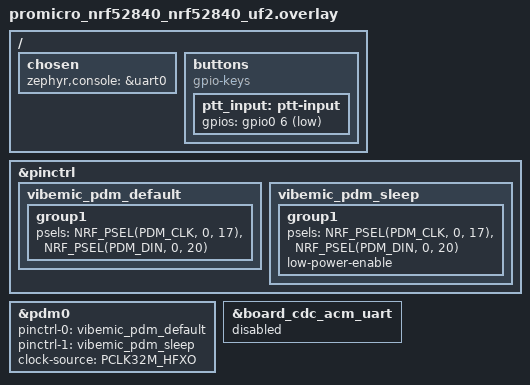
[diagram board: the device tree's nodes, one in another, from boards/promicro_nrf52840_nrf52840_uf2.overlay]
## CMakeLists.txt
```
cmake_minimum_required(VERSION 3.20.0)
find_package(Zephyr REQUIRED HINTS $ENV{ZEPHYR_BASE})
project(vibemic_transmitter)
target_include_directories(app PRIVATE ../common)
target_sources(app PRIVATE src/capture.c)

if(CONFIG_VIBEMIC_MIC_PROBE)
  target_sources(app PRIVATE src/mic_probe.c)
else()
  target_sources(app PRIVATE src/main.c src/dynamics.c src/battery.c ../common/link.c ../common/protocol.c)
endif()

target_sources_ifdef(CONFIG_VIBEMIC_DIRECT_USB app PRIVATE
                     ../common/usb.c ../common/session.c ../common/playout.c)
```

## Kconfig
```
mainmenu "VibeMic transmitter"

source "Kconfig.zephyr"

config VIBEMIC_MIC_PROBE
	bool "Capture a three-second PCM clip over USB CDC ACM"

config VIBEMIC_APPROVAL_GESTURE
	bool "Distinguish a double tap from a dictation hold"
	default y if BOARD_PROMICRO_NRF52840

config VIBEMIC_DIRECT_USB
	bool "Offer the microphone and PTT directly to a USB host"
	default y if BOARD_PROMICRO_NRF52840
	depends on BOARD_PROMICRO_NRF52840 && !VIBEMIC_MIC_PROBE
	select USB_DEVICE_STACK_NEXT
	select USBD_AUDIO2_CLASS
	select USBD_HID_SUPPORT
	select HWINFO

choice VIBEMIC_BATTERY_SENSOR
	prompt "Transmitter battery measurement circuit"
	default VIBEMIC_BATTERY_NONE
	depends on BOARD_PROMICRO_NRF52840 && !VIBEMIC_MIC_PROBE

config VIBEMIC_BATTERY_NONE
	bool "Unknown circuit (report power only)"

config VIBEMIC_BATTERY_VDDH
	bool "nice!nano v2: internal VDDH / 5"
	select ADC

config VIBEMIC_BATTERY_DIVIDER
	bool "nice!nano v1: AIN2, 806k + 2M divider"
	select ADC

endchoice
```

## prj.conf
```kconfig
CONFIG_AUDIO=y
CONFIG_AUDIO_DMIC=y
CONFIG_REGULATOR=y
CONFIG_GPIO=y
CONFIG_CLOCK_CONTROL=y
CONFIG_ENTROPY_GENERATOR=y
CONFIG_ENTROPY_DEVICE_RANDOM_GENERATOR=y

CONFIG_ESB=y
CONFIG_ESB_CLOCK_INIT=y
CONFIG_ESB_MAX_PAYLOAD_LENGTH=172
CONFIG_ESB_PIPE_COUNT=1
CONFIG_ESB_DEFAULT_RF_CHANNEL=76

CONFIG_MAIN_STACK_SIZE=2048
CONFIG_BOARD_SERIAL_BACKEND_CDC_ACM=n
CONFIG_LOG=y
CONFIG_SERIAL=y
CONFIG_CONSOLE=y
CONFIG_UART_CONSOLE=y
```

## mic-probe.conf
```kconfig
CONFIG_VIBEMIC_MIC_PROBE=y
CONFIG_AUDIO=y
CONFIG_AUDIO_DMIC=y
CONFIG_REGULATOR=y
CONFIG_CLOCK_CONTROL=y
CONFIG_USB_DEVICE_STACK_NEXT=y
CONFIG_CDC_ACM_SERIAL_INITIALIZE_AT_BOOT=y
CONFIG_CDC_ACM_SERIAL_VID=0x1209
CONFIG_CDC_ACM_SERIAL_PID=0x0002
CONFIG_CDC_ACM_SERIAL_MANUFACTURER_STRING="VibeMic"
CONFIG_CDC_ACM_SERIAL_PRODUCT_STRING="VibeMic PDM Probe"
CONFIG_UART_CONSOLE=n
CONFIG_UART_LINE_CTRL=y
CONFIG_MAIN_STACK_SIZE=2048
```

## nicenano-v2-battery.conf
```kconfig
# Only use on a confirmed nice!nano v2 power circuit, not an unverified clone.
CONFIG_VIBEMIC_BATTERY_VDDH=y
```

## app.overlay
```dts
#include <zephyr/dt-bindings/gpio/gpio.h>

/ {
	chosen {
		zephyr,console = &uart0;
	};

	buttons {
		compatible = "gpio-keys";

		ptt_input: ptt-input {
			gpios = <&xiao_d 0 (GPIO_PULL_UP | GPIO_ACTIVE_LOW)>;
		};
	};

	msm261d3526hicpm-c-en {
		regulator-boot-on;
	};
};

&pdm0 {
	status = "okay";
	clock-source = "PCLK32M_HFXO";
};

&board_cdc_acm_uart {
	status = "disabled";
};
```

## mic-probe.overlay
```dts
&board_cdc_acm_uart {
	status = "okay";
	hw-flow-control; /* uart_poll_out waits for TX space instead of discarding bytes. */
};
```

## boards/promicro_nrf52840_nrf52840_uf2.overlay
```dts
#include <zephyr/dt-bindings/gpio/gpio.h>
#include <zephyr/dt-bindings/pinctrl/nrf-pinctrl.h>
#include "../../common/usb-audio.dtsi"

/ {
	chosen {
		zephyr,console = &uart0;
	};

	buttons {
		compatible = "gpio-keys";

		ptt_input: ptt-input {
			gpios = <&gpio0 6 (GPIO_PULL_UP | GPIO_ACTIVE_LOW)>;
		};
	};
};

&pinctrl {
	vibemic_pdm_default: vibemic_pdm_default {
		group1 {
			psels = <NRF_PSEL(PDM_CLK, 0, 17)>,
				<NRF_PSEL(PDM_DIN, 0, 20)>;
		};
	};

	vibemic_pdm_sleep: vibemic_pdm_sleep {
		group1 {
			psels = <NRF_PSEL(PDM_CLK, 0, 17)>,
				<NRF_PSEL(PDM_DIN, 0, 20)>;
			low-power-enable;
		};
	};
};

&pdm0 {
	status = "okay";
	pinctrl-0 = <&vibemic_pdm_default>;
	pinctrl-1 = <&vibemic_pdm_sleep>;
	pinctrl-names = "default", "sleep";
	clock-source = "PCLK32M_HFXO";
};

&board_cdc_acm_uart {
	status = "disabled";
};
```

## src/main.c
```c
#include "capture.h"
#include "battery.h"
#include "dynamics.h"
#include "link.h"
#include "protocol.h"
#include "ptt_gesture.h"
#include "session.h"
#include "usb.h"

#include <errno.h>
#include <string.h>
#include <zephyr/drivers/gpio.h>
#include <zephyr/kernel.h>
#include <zephyr/logging/log.h>
#include <zephyr/random/random.h>
#include <zephyr/sys/atomic.h>

LOG_MODULE_REGISTER(vibemic_tx, LOG_LEVEL_INF);

#define HOLD_BLOCKS (IS_ENABLED(CONFIG_VIBEMIC_APPROVAL_GESTURE) ? VM_HOLD_BLOCKS : 0u)
#define PRE_ROLL_BLOCKS (120u / VM_BLOCK_MS + HOLD_BLOCKS)
#define TX_QUEUE_BLOCKS (40u + HOLD_BLOCKS)
#define DEBOUNCE_BLOCKS 2u
#define UP_RESTARTS 2u
#define UP_RESTART_DELAY_MS 12u

static const struct gpio_dt_spec ptt = GPIO_DT_SPEC_GET(DT_NODELABEL(ptt_input), gpios);
static const struct gpio_dt_spec led = GPIO_DT_SPEC_GET(DT_ALIAS(led0), gpios);
static int16_t pre_roll[PRE_ROLL_BLOCKS][VM_BLOCK_SAMPLES];

K_MSGQ_DEFINE(tx_queue, sizeof(struct esb_payload), TX_QUEUE_BLOCKS, 4);
K_SEM_DEFINE(tx_done, 0, 1);
static atomic_t tx_attempts;
static atomic_t tx_ok;

static void on_radio(const struct esb_evt *event)
{
	if (event->evt_id == ESB_EVENT_TX_SUCCESS || event->evt_id == ESB_EVENT_TX_FAILED) {
		atomic_set(&tx_attempts, event->tx_attempts);
		atomic_set(&tx_ok, event->evt_id == ESB_EVENT_TX_SUCCESS);
		k_sem_give(&tx_done);
	}
}

static bool send_packet(const struct esb_payload *packet, uint32_t *retries)
{
	int err = esb_write_payload(packet);
	unsigned restarts = packet->data[1] == VM_PTT_UP ? UP_RESTARTS : 0u;

	if (err != 0) {
		LOG_WRN("ESB write: %d", err);
		return false;
	}
	for (;;) {
		k_sem_take(&tx_done, K_FOREVER);
		uint32_t attempts = atomic_get(&tx_attempts);

		*retries += attempts > 0 ? attempts - 1u : 0u;
		if (atomic_get(&tx_ok)) {
			return true;
		}
		if (restarts == 0) {
			break;
		}
		restarts--;
		/* On TX_FAILED ESB retains the payload and PID. Spread the final
		 * edge across separate bursts without enqueuing another packet.
		 */
		k_sleep(K_MSEC(UP_RESTART_DELAY_MS));
		err = esb_start_tx();
		if (err != 0) {
			LOG_WRN("ESB restart: %d", err);
			break;
		}
		(*retries)++;
	}
	err = esb_flush_tx();
	if (err != 0) {
		LOG_WRN("ESB flush: %d", err);
	}
	return false;
}

static void radio_worker(void *a, void *b, void *c)
{
	struct esb_payload packet;
	uint32_t sent = 0, failed = 0, retries = 0;
	uint64_t ack_sum_us = 0;
	uint32_t ack_max_us = 0;

	ARG_UNUSED(a);
	ARG_UNUSED(b);
	ARG_UNUSED(c);
	for (;;) {
		k_msgq_get(&tx_queue, &packet, K_FOREVER);

		/* Only one item in the ESB FIFO. */
		uint32_t started = k_cycle_get_32();
		if (send_packet(&packet, &retries)) {
			uint32_t elapsed = k_cyc_to_us_ceil32(k_cycle_get_32() - started);

			sent++;
			ack_sum_us += elapsed;
			ack_max_us = MAX(ack_max_us, elapsed);
		} else {
			failed++;
		}
		if (packet.data[1] == VM_PTT_UP) {
			uint32_t ack_avg_us = sent ? ack_sum_us / sent : 0;

			LOG_INF("Session TX: %u ACK, %u failed, %u retries, ACK avg/max %u/%u us",
				sent, failed, retries, ack_avg_us, ack_max_us);
			sent = failed = retries = 0;
			ack_sum_us = ack_max_us = 0;
		}
	}
}

K_THREAD_STACK_DEFINE(radio_stack, 1536);
static struct k_thread radio_thread;

static bool enqueue(uint8_t flag, uint32_t session, uint32_t block, const int16_t *pcm)
{
	struct esb_payload packet = {
		.pipe = 0,
		.noack = false,
		.length = flag == VM_AUDIO ? VM_AUDIO_BYTES : VM_HEADER_BYTES,
	};

	/* Preserve room for both edges even when audio is backed up. */
	if (flag == VM_AUDIO && k_msgq_num_free_get(&tx_queue) <= 2u) {
		return false;
	}
	vm_encode(packet.data, flag, session, block, pcm);
	if (k_msgq_put(&tx_queue, &packet, K_NO_WAIT) != 0) {
		LOG_WRN("TX queue full; dropped PTT edge %u", flag);
		return false;
	}
	return true;
}

static bool send_audio(uint32_t usb, enum vm_flag flag, uint32_t session,
		       uint32_t block, const int16_t *pcm)
{
	if (IS_ENABLED(CONFIG_VIBEMIC_DIRECT_USB) && usb) {
		uint8_t wire[VM_AUDIO_BYTES];

		if (usb != vm_usb_connection()) {
			return false;
		}
		vm_encode(wire, flag, session, block, pcm);
		vm_session_accept(wire, flag == VM_AUDIO ? VM_AUDIO_BYTES : VM_HEADER_BYTES,
				  0, k_uptime_get_32());
		return true;
	}
	return enqueue(flag, session, block, pcm);
}

int main(void)
{
	int16_t pcm[VM_BLOCK_SAMPLES];
	uint32_t session = sys_rand32_get();
	uint32_t block = 0;
	uint32_t dropped = 0;
	uint32_t capture_block = 0;
	uint32_t usb = 0, press_usb = 0;
	uint32_t battery_at = 0;
	unsigned write = 0, have = 0, debounce = 0;
	struct vm_ptt_gesture ptt_state = {0};
	struct vm_dynamics dynamics;
	int err;

	if (!gpio_is_ready_dt(&ptt) || !gpio_is_ready_dt(&led)) {
		return -ENODEV;
	}
	err = gpio_pin_configure_dt(&ptt, GPIO_INPUT);
	if (err == 0) {
		err = gpio_pin_configure_dt(&led, GPIO_OUTPUT_INACTIVE);
	}
	if (err == 0) {
		err = vm_radio_init(ESB_MODE_PTX, on_radio);
	}
	if (err == 0) {
		err = vm_capture_start();
	}
	if (err != 0) {
		LOG_ERR("TX initialization failed: %d", err);
		return err;
	}
	if (IS_ENABLED(CONFIG_VIBEMIC_DIRECT_USB)) {
		err = vm_usb_init();
		if (err != 0) {
			LOG_WRN("Direct USB initialization failed: %d", err);
		}
	}

	k_thread_create(&radio_thread, radio_stack, K_THREAD_STACK_SIZEOF(radio_stack),
			radio_worker, NULL, NULL, NULL, 4, 0, K_NO_WAIT);
	vm_dynamics_reset(&dynamics);
	vm_battery_start();

	for (;;) {
		err = vm_capture_read(pcm);
		if (err != 0) {
			/* Release on capture failure; RX watchdog covers a lost UP. */
			if (ptt_state.recording && !press_usb) {
				enqueue(VM_PTT_UP, session, block, NULL);
			}
			if (IS_ENABLED(CONFIG_VIBEMIC_DIRECT_USB)) {
				vm_usb_stop();
			}
			gpio_pin_set_dt(&led, 0);
			vm_capture_stop();
			LOG_ERR("PDM stopped: %d; reset transmitter to retry", err);
			return err;
		}
		vm_dynamics_process(&dynamics, pcm);

		if (IS_ENABLED(CONFIG_VIBEMIC_DIRECT_USB) && usb != vm_usb_connection()) {
			usb = vm_usb_connection();
			vm_session_reset();
			ptt_state.armed = false;
			if (press_usb && ptt_state.recording) {
				gpio_pin_set_dt(&led, 0);
			}
		}
		int level = gpio_pin_get_dt(&ptt);
		bool pressed = ptt_state.pressed;

		if (level < 0 || (level != 0) == pressed) {
			debounce = 0;
		} else if (++debounce == DEBOUNCE_BLOCKS) {
			debounce = 0;
			pressed = level != 0;
		}
		if (pressed && !ptt_state.pressed) {
			/* Keep the same output for the whole press, including its audio tail. */
			press_usb = usb;
		}
		enum vm_flag event = vm_ptt_step(&ptt_state, pressed, capture_block++,
					       IS_ENABLED(CONFIG_VIBEMIC_APPROVAL_GESTURE));

		if (event == VM_PTT_DOWN) {
			session++;
			block = 0;
			dropped = 0;
			send_audio(press_usb, VM_PTT_DOWN, session, block, NULL);
			gpio_pin_set_dt(&led, !press_usb || press_usb == usb);
			for (unsigned i = 0; i < have; i++) {
				unsigned index = (write + PRE_ROLL_BLOCKS - have + i) %
						 PRE_ROLL_BLOCKS;
				if (!send_audio(press_usb, VM_AUDIO, session, block++, pre_roll[index])) {
					dropped++;
				}
			}
		}
		if (ptt_state.recording || event == VM_PTT_UP) {
			if (!send_audio(press_usb, VM_AUDIO, session, block++, pcm)) {
				dropped++;
			}
		}
		if (event == VM_PTT_UP) {
			/* The UP fence carries the exact end timestamp, even if audio was lost. */
			send_audio(press_usb, VM_PTT_UP, session, block, NULL);
			gpio_pin_set_dt(&led, 0);
			if (dropped != 0) {
				LOG_WRN("TX queue dropped %u audio blocks", dropped);
			}
		}
		if (event == VM_APPROVAL_ARM) {
			session++;
		}
		if (event == VM_APPROVAL_ARM || event == VM_APPROVAL_COMMIT) {
			/* Keep the gesture on one transport and out of the radio audio backlog. */
			if (press_usb == usb && (usb || k_msgq_num_used_get(&tx_queue) == 0)) {
				send_audio(press_usb, event, session, 0, NULL);
			} else {
				ptt_state.armed = false;
			}
		}
		if (IS_ENABLED(CONFIG_VIBEMIC_DIRECT_USB) && usb == vm_usb_connection() && usb) {
			vm_session_tick(k_uptime_get_32());
		}

		uint32_t now = k_uptime_get_32();
		if (now - battery_at >= 5000u && !ptt_state.pressed && !ptt_state.recording &&
		    !ptt_state.armed && k_msgq_num_used_get(&tx_queue) == 0) {
			struct vm_battery battery = vm_battery_read();
			struct esb_payload packet = {
				.pipe = 0, .noack = false, .length = VM_BATTERY_BYTES,
			};
			vm_encode_battery(packet.data, &battery);
			if (usb) {
				vm_session_accept(packet.data, packet.length, 0, now);
			} else {
				k_msgq_put(&tx_queue, &packet, K_NO_WAIT);
			}
			battery_at = now;
		}

		memcpy(pre_roll[write], pcm, sizeof(pcm));
		write = (write + 1u) % PRE_ROLL_BLOCKS;
		if (have < PRE_ROLL_BLOCKS) {
			have++;
		}
	}
}
```

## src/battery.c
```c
#include "battery.h"

#include <hal/nrf_power.h>
#include <zephyr/kernel.h>
#include <zephyr/sys/atomic.h>
#if defined(CONFIG_VIBEMIC_BATTERY_VDDH) || defined(CONFIG_VIBEMIC_BATTERY_DIVIDER)
#include <zephyr/dt-bindings/adc/nrf-saadc.h>
#include <zephyr/drivers/adc.h>
#endif

static atomic_t voltage;

#if defined(CONFIG_VIBEMIC_BATTERY_VDDH) || defined(CONFIG_VIBEMIC_BATTERY_DIVIDER)
static const struct device *const adc = DEVICE_DT_GET(DT_NODELABEL(adc));
static void sample(struct k_work *work);
K_WORK_DELAYABLE_DEFINE(measurement, sample);

static void sample(struct k_work *work)
{
	ARG_UNUSED(work);
	int16_t raw;
	struct adc_sequence sequence = {
		.channels = BIT(0), .buffer = &raw, .buffer_size = sizeof(raw),
		.resolution = 12, .oversampling = 4,
	};
	int32_t mv = 0;
	if (adc_read(adc, &sequence) == 0) {
		mv = raw;
		if (adc_raw_to_millivolts(adc_ref_internal(adc), ADC_GAIN_1_6, 12, &mv) == 0) {
#if defined(CONFIG_VIBEMIC_BATTERY_VDDH)
			mv *= 5;
#else
			mv = (mv * 2806 + 1000) / 2000;
#endif
		} else {
			mv = 0;
		}
	}
	atomic_set(&voltage, mv >= 2800 && mv <= 4350 ? mv : 0);
	k_work_reschedule(&measurement, K_SECONDS(5));
}
#endif

void vm_battery_start(void)
{
#if defined(CONFIG_VIBEMIC_BATTERY_VDDH) || defined(CONFIG_VIBEMIC_BATTERY_DIVIDER)
	const struct adc_channel_cfg channel = {
		.gain = ADC_GAIN_1_6, .reference = ADC_REF_INTERNAL,
		.acquisition_time = ADC_ACQ_TIME(ADC_ACQ_TIME_MICROSECONDS, 40),
		.channel_id = 0,
#if defined(CONFIG_VIBEMIC_BATTERY_VDDH)
		.input_positive = NRF_SAADC_VDDHDIV5,
#else
		.input_positive = NRF_SAADC_AIN2,
#endif
	};
	if (device_is_ready(adc) && adc_channel_setup(adc, &channel) == 0) {
		k_work_reschedule(&measurement, K_NO_WAIT);
	}
#endif
}

struct vm_battery vm_battery_read(void)
{
	uint16_t mv = (uint16_t)atomic_get(&voltage);
	bool usb = nrf_power_usbregstatus_vbusdet_get(NRF_POWER);

	return (struct vm_battery){ .millivolts = mv,
		.flags = (mv ? VM_BATTERY_VALID : 0) | (usb ? VM_BATTERY_USB_POWER : 0) };
}
```

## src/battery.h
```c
#ifndef VIBEMIC_BATTERY_H
#define VIBEMIC_BATTERY_H

#include "protocol.h"

void vm_battery_start(void);
struct vm_battery vm_battery_read(void);

#endif
```

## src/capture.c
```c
#include "capture.h"

#include <errno.h>
#include <string.h>
#include <zephyr/audio/dmic.h>
#include <zephyr/device.h>
#include <zephyr/kernel.h>

static const struct device *const mic = DEVICE_DT_GET(DT_NODELABEL(pdm0));
K_MEM_SLAB_DEFINE(pcm_slab, VM_PCM_BYTES, 8, 4);

int vm_capture_start(void)
{
	struct pcm_stream_cfg stream = {
		.pcm_rate = VM_SAMPLE_RATE,
		.pcm_width = 16,
		.block_size = VM_PCM_BYTES,
		.mem_slab = &pcm_slab,
	};
	struct dmic_cfg config = {
		.io = {
			.min_pdm_clk_freq = 1000000,
			.max_pdm_clk_freq = 3500000,
			.min_pdm_clk_dc = 40,
			.max_pdm_clk_dc = 60,
		},
		.streams = &stream,
		.channel = {
			.req_num_streams = 1,
			.req_num_chan = 1,
			.req_chan_map_lo = dmic_build_channel_map(0, 0, PDM_CHAN_LEFT),
		},
	};

	if (!device_is_ready(mic)) {
		return -ENODEV;
	}
	int err = dmic_configure(mic, &config);

	return err != 0 ? err : dmic_trigger(mic, DMIC_TRIGGER_START);
}

int vm_capture_read(int16_t *pcm)
{
	void *block;
	uint32_t size;
	int err = dmic_read(mic, 0, &block, &size, 50);

	if (err != 0) {
		return err;
	}
	if (size == VM_PCM_BYTES) {
		memcpy(pcm, block, size);
	}
	k_mem_slab_free(&pcm_slab, block);
	return size == VM_PCM_BYTES ? 0 : -EIO;
}

int vm_capture_stop(void)
{
	return dmic_trigger(mic, DMIC_TRIGGER_STOP);
}
```

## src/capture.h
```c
#ifndef VIBEMIC_CAPTURE_H
#define VIBEMIC_CAPTURE_H

#include "protocol.h"

int vm_capture_start(void);
int vm_capture_read(int16_t *pcm);
int vm_capture_stop(void);

#endif
```

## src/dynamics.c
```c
#include "dynamics.h"

#define GAIN_ONE 4096
#define MAKEUP_GAIN (4 * GAIN_ONE)
#define COMPRESSOR_THRESHOLD 823u /* -32 dBFS RMS */
#define PEAK_CEILING 26028u       /* -2 dBFS sample peak */
#define RELEASE_BLOCKS 16         /* About 80 ms at 5 ms per block. */

static uint32_t integer_sqrt(uint32_t value)
{
	uint32_t root = 0;
	uint32_t bit = 1u << 30;

	while (bit > value) {
		bit >>= 2;
	}
	while (bit != 0) {
		if (value >= root + bit) {
			value -= root + bit;
			root = (root >> 1) + bit;
		} else {
			root >>= 1;
		}
		bit >>= 2;
	}
	return root;
}

void vm_dynamics_reset(struct vm_dynamics *state)
{
	state->gain_q12 = MAKEUP_GAIN;
}

void vm_dynamics_process(struct vm_dynamics *state, int16_t pcm[VM_BLOCK_SAMPLES])
{
	uint64_t energy = 0;
	uint32_t peak = 0;

	for (unsigned i = 0; i < VM_BLOCK_SAMPLES; i++) {
		int32_t sample = pcm[i];
		uint32_t magnitude = (uint32_t)(sample < 0 ? -sample : sample);

		energy += (uint32_t)(sample * sample);
		if (magnitude > peak) {
			peak = magnitude;
		}
	}

	uint32_t rms = integer_sqrt((uint32_t)(energy / VM_BLOCK_SAMPLES));
	int32_t target = MAKEUP_GAIN;

	if (rms > COMPRESSOR_THRESHOLD) {
		/* A 2:1 ratio halves the rise in output dB above the threshold. */
		uint64_t squared = (uint64_t)MAKEUP_GAIN * MAKEUP_GAIN * COMPRESSOR_THRESHOLD;

		target = (int32_t)integer_sqrt((uint32_t)(squared / rms));
	}

	int32_t start = state->gain_q12;
	if (peak != 0) {
		int32_t limit = (int32_t)(PEAK_CEILING * GAIN_ONE / peak);

		/* Both ends of the ramp must fit under the loudest sample in this block. */
		start = start < limit ? start : limit;
		target = target < limit ? target : limit;
	}

	int32_t end = target;
	if (target > start) {
		end = start + (target - start + RELEASE_BLOCKS - 1) / RELEASE_BLOCKS;
	}
	for (unsigned i = 0; i < VM_BLOCK_SAMPLES; i++) {
		int32_t gain = start + (end - start) * (int32_t)(i + 1) / (int32_t)VM_BLOCK_SAMPLES;

		pcm[i] = (int16_t)((int32_t)pcm[i] * gain / GAIN_ONE);
	}
	state->gain_q12 = end;
}
```

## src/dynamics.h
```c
#ifndef VIBEMIC_DYNAMICS_H
#define VIBEMIC_DYNAMICS_H

#include "protocol.h"

struct vm_dynamics {
	int32_t gain_q12;
};

void vm_dynamics_reset(struct vm_dynamics *state);
void vm_dynamics_process(struct vm_dynamics *state, int16_t pcm[VM_BLOCK_SAMPLES]);

#endif
```

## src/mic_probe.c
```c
#include "capture.h"

#include <errno.h>
#include <zephyr/device.h>
#include <zephyr/drivers/uart.h>
#include <zephyr/kernel.h>

#define PROBE_SECONDS 3u
#define PROBE_BLOCKS (PROBE_SECONDS * 1000u / VM_BLOCK_MS)

static const struct device *const port = DEVICE_DT_GET(DT_NODELABEL(board_cdc_acm_uart));
static int16_t clip[PROBE_BLOCKS][VM_BLOCK_SAMPLES];

static void send_tag(const char tag[4])
{
	for (unsigned i = 0; i < 4; i++) {
		uart_poll_out(port, tag[i]);
	}
}

static int record_clip(void)
{
	int err = vm_capture_start();

	if (err != 0) {
		return err;
	}
	for (unsigned i = 0; i < PROBE_BLOCKS && err == 0; i++) {
		err = vm_capture_read(clip[i]);
	}
	int stop_err = vm_capture_stop();

	return err != 0 ? err : stop_err;
}

int main(void)
{
	if (!device_is_ready(port)) {
		return -ENODEV;
	}
	for (;;) {
		uint32_t dtr = 0;
		unsigned char command;

		if (uart_line_ctrl_get(port, UART_LINE_CTRL_DTR, &dtr) == 0 && dtr &&
		    uart_poll_in(port, &command) == 0 && command == 'R') {
			if (record_clip() != 0) {
				send_tag("VERR");
				continue;
			}
			send_tag("VMIC");
			for (unsigned i = 0; i < PROBE_BLOCKS; i++) {
				for (unsigned j = 0; j < VM_BLOCK_SAMPLES; j++) {
					uint16_t sample = (uint16_t)clip[i][j];

					uart_poll_out(port, (uint8_t)sample);
					uart_poll_out(port, (uint8_t)(sample >> 8));
				}
			}
		} else {
			k_sleep(K_MSEC(10));
		}
	}
}
```

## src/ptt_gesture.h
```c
#ifndef VIBEMIC_PTT_GESTURE_H
#define VIBEMIC_PTT_GESTURE_H

#include "protocol.h"

#define VM_MIN_TAP_BLOCKS (25u / VM_BLOCK_MS)
#define VM_HOLD_BLOCKS (125u / VM_BLOCK_MS)
#define VM_TAP_GAP_BLOCKS (350u / VM_BLOCK_MS)

struct vm_ptt_gesture {
	uint32_t pressed_at, tapped_at;
	bool pressed, recording, armed;
};

/* Time is measured in captured audio blocks, after GPIO debounce. */
static inline enum vm_flag vm_ptt_step(struct vm_ptt_gesture *ptt, bool pressed,
				       uint32_t now, bool gestures)
{
	if (pressed && !ptt->pressed) {
		ptt->pressed_at = now;
		ptt->armed = ptt->armed && now - ptt->tapped_at <= VM_TAP_GAP_BLOCKS;
	}
	bool was_pressed = ptt->pressed;
	ptt->pressed = pressed;
	uint32_t held = now - ptt->pressed_at;

	if (pressed && !ptt->recording && (!gestures || held >= VM_HOLD_BLOCKS)) {
		ptt->armed = false;
		ptt->recording = true;
		return VM_PTT_DOWN;
	}
	if (pressed || !was_pressed) {
		return 0;
	}
	if (ptt->recording) {
		ptt->recording = false;
		return VM_PTT_UP;
	}
	if (held < VM_MIN_TAP_BLOCKS) {
		ptt->armed = false;
		return 0;
	}
	if (ptt->armed) {
		ptt->armed = false;
		return VM_APPROVAL_COMMIT;
	}
	ptt->tapped_at = now;
	ptt->armed = true;
	return VM_APPROVAL_ARM;
}

#endif
```
